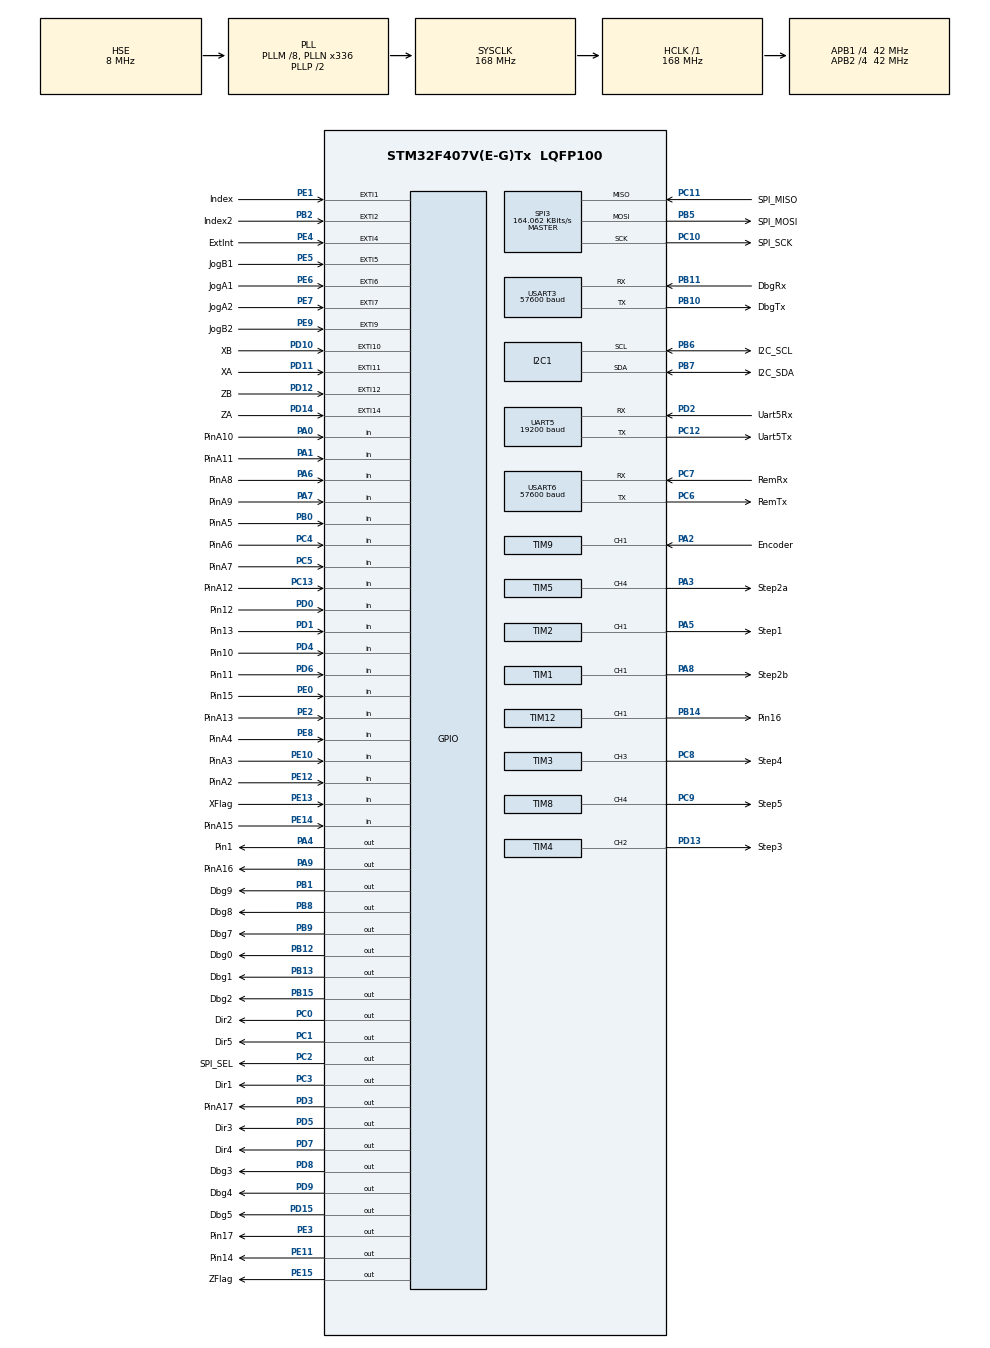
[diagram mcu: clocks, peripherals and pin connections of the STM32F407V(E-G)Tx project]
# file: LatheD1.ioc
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IWDG.Prescaler=IWDG_PRESCALER_32
Mcu.Family=STM32F4
Mcu.Name=STM32F407V(E-G)Tx
Mcu.Package=LQFP100
NVIC.EXTI15_10_IRQn=true\:5\:0\:true\:false\:false\:true\:false\:true
NVIC.EXTI2_IRQn=true\:5\:0\:true\:false\:false\:true\:false\:true
NVIC.EXTI4_IRQn=true\:5\:0\:true\:false\:false\:true\:false\:true
NVIC.EXTI9_5_IRQn=true\:5\:0\:true\:false\:false\:true\:false\:true
NVIC.PriorityGroup=NVIC_PRIORITYGROUP_4
NVIC.SPI3_IRQn=true\:6\:0\:true\:false\:false\:true\:false\:true
NVIC.TIM1_BRK_TIM9_IRQn=true\:6\:0\:true\:false\:false\:true\:false\:true
NVIC.TIM1_TRG_COM_TIM11_IRQn=true\:6\:0\:true\:false\:false\:true\:false\:true
NVIC.TIM1_UP_TIM10_IRQn=true\:4\:0\:true\:false\:false\:true\:false\:true
NVIC.TIM2_IRQn=true\:3\:0\:true\:false\:false\:true\:false\:true
NVIC.TIM3_IRQn=true\:2\:0\:true\:false\:false\:true\:false\:true
NVIC.TIM4_IRQn=true\:4\:0\:true\:false\:false\:true\:false\:true
NVIC.TIM5_IRQn=true\:2\:0\:true\:false\:false\:true\:false\:true
NVIC.TIM7_IRQn=true\:5\:0\:true\:false\:false\:true\:false\:true
NVIC.TIM8_BRK_TIM12_IRQn=true\:5\:0\:true\:false\:false\:true\:false\:true
NVIC.TIM8_TRG_COM_TIM14_IRQn=true\:0\:0\:false\:false\:false\:true\:false\:true
NVIC.TIM8_UP_TIM13_IRQn=true\:5\:0\:true\:false\:false\:true\:false\:true
NVIC.UART5_IRQn=true\:6\:0\:true\:false\:false\:true\:false\:true
NVIC.USART6_IRQn=true\:6\:0\:true\:false\:false\:true\:false\:true
PA0-WKUP.GPIO_Label=PinA10
PA0-WKUP.Signal=GPIO_Input
PA1.GPIO_Label=PinA11
PA1.Signal=GPIO_Input
PA13.Mode=JTAG_5_pins
PA13.Signal=SYS_JTMS-SWDIO
PA14.Mode=JTAG_5_pins
PA14.Signal=SYS_JTCK-SWCLK
PA15.Mode=JTAG_5_pins
PA15.Signal=SYS_JTDI
PA2.GPIO_Label=Encoder
PA2.Signal=S_TIM9_CH1
PA3.GPIO_Label=Step2a
PA3.Signal=S_TIM5_CH4
PA4.GPIO_Label=Pin1
PA4.Signal=GPIO_Output
PA5.GPIO_Label=Step1
PA5.Signal=S_TIM2_CH1_ETR
PA6.GPIO_Label=PinA8
PA6.Signal=GPIO_Input
PA7.GPIO_Label=PinA9
PA7.Signal=GPIO_Input
PA8.GPIO_Label=Step2b
PA8.Signal=S_TIM1_CH1
PA9.GPIO_Label=PinA16
PA9.Signal=GPIO_Output
PB0.GPIO_Label=PinA5
PB0.Signal=GPIO_Input
PB1.GPIO_Label=Dbg9
PB1.Signal=GPIO_Output
PB10.GPIO_Label=DbgTx
PB10.Mode=Asynchronous
PB10.Signal=USART3_TX
PB11.GPIO_Label=DbgRx
PB11.Mode=Asynchronous
PB11.Signal=USART3_RX
PB12.GPIO_Label=Dbg0
PB12.Signal=GPIO_Output
PB13.GPIO_Label=Dbg1
PB13.Signal=GPIO_Output
PB14.GPIO_Label=Pin16
PB14.Signal=S_TIM12_CH1
PB15.GPIO_Label=Dbg2
PB15.Signal=GPIO_Output
PB2.GPIO_Label=Index2
PB2.Signal=GPXTI2
PB3.Mode=JTAG_5_pins
PB3.Signal=SYS_JTDO-SWO
PB4.Mode=JTAG_5_pins
PB4.Signal=SYS_JTRST
PB5.GPIO_Label=SPI_MOSI
PB5.Mode=Full_Duplex_Master
PB5.Signal=SPI3_MOSI
PB6.GPIO_Label=I2C_SCL
PB6.GPIO_Pu=GPIO_PULLUP
PB6.Mode=I2C
PB6.Signal=I2C1_SCL
PB7.GPIO_Label=I2C_SDA
PB7.GPIO_Pu=GPIO_PULLUP
PB7.Mode=I2C
PB7.Signal=I2C1_SDA
PB8.GPIO_Label=Dbg8
PB8.Signal=GPIO_Output
PB9.GPIO_Label=Dbg7
PB9.Signal=GPIO_Output
PC0.GPIO_Label=Dir2
PC0.Signal=GPIO_Output
PC1.GPIO_Label=Dir5
PC1.Signal=GPIO_Output
PC10.GPIO_Label=SPI_SCK
PC10.Mode=Full_Duplex_Master
PC10.Signal=SPI3_SCK
PC11.GPIO_Label=SPI_MISO
PC11.Mode=Full_Duplex_Master
PC11.Signal=SPI3_MISO
PC12.GPIO_Label=Uart5Tx
PC12.Mode=Asynchronous
PC12.Signal=UART5_TX
PC13-ANTI_TAMP.GPIO_Label=PinA12
PC13-ANTI_TAMP.Signal=GPIO_Input
PC2.GPIO_Label=SPI_SEL
PC2.Signal=GPIO_Output
PC3.GPIO_Label=Dir1
PC3.Signal=GPIO_Output
PC4.GPIO_Label=PinA6
PC4.Signal=GPIO_Input
PC5.GPIO_Label=PinA7
PC5.Signal=GPIO_Input
PC6.GPIO_Label=RemTx
PC6.Mode=Asynchronous
PC6.Signal=USART6_TX
PC7.GPIO_Label=RemRx
PC7.Mode=Asynchronous
PC7.Signal=USART6_RX
PC8.GPIO_Label=Step4
PC8.Signal=S_TIM3_CH3
PC9.GPIO_Label=Step5
PC9.GPIO_Speed=GPIO_SPEED_FREQ_LOW
PC9.Signal=S_TIM8_CH4
PD0.GPIO_Label=Pin12
PD0.Signal=GPIO_Input
PD1.GPIO_Label=Pin13
PD1.Signal=GPIO_Input
PD10.GPIO_Label=XB
PD10.GPIO_ModeDefaultEXTI=GPIO_MODE_IT_RISING_FALLING
PD10.Signal=GPXTI10
PD11.GPIO_Label=XA
PD11.GPIO_ModeDefaultEXTI=GPIO_MODE_IT_RISING_FALLING
PD11.Signal=GPXTI11
PD12.GPIO_Label=ZB
PD12.GPIO_ModeDefaultEXTI=GPIO_MODE_IT_RISING_FALLING
PD12.Signal=GPXTI12
PD13.GPIO_Label=Step3
PD13.Signal=S_TIM4_CH2
PD14.GPIO_Label=ZA
PD14.GPIO_ModeDefaultEXTI=GPIO_MODE_IT_RISING_FALLING
PD14.Signal=GPXTI14
PD15.GPIO_Label=Dbg5
PD15.Signal=GPIO_Output
PD2.GPIO_Label=Uart5Rx
PD2.Mode=Asynchronous
PD2.Signal=UART5_RX
PD3.GPIO_Label=PinA17
PD3.Signal=GPIO_Output
PD4.GPIO_Label=Pin10
PD4.Signal=GPIO_Input
PD5.GPIO_Label=Dir3
PD5.Signal=GPIO_Output
PD6.GPIO_Label=Pin11
PD6.Signal=GPIO_Input
PD7.GPIO_Label=Dir4
PD7.Signal=GPIO_Output
PD8.GPIO_Label=Dbg3
PD8.Signal=GPIO_Output
PD9.GPIO_Label=Dbg4
PD9.Signal=GPIO_Output
PE0.GPIO_Label=Pin15
PE0.Signal=GPIO_Input
PE1.GPIO_Label=Index
PE1.Signal=GPXTI1
PE10.GPIO_Label=PinA3
PE10.Signal=GPIO_Input
PE11.GPIO_Label=Pin14
PE11.Signal=GPIO_Output
PE12.GPIO_Label=PinA2
PE12.Signal=GPIO_Input
PE13.GPIO_Label=XFlag
PE13.Signal=GPIO_Input
PE14.GPIO_Label=PinA15
PE14.Signal=GPIO_Input
PE15.GPIO_Label=ZFlag
PE15.Signal=GPIO_Output
PE2.GPIO_Label=PinA13
PE2.Signal=GPIO_Input
PE3.GPIO_Label=Pin17
PE3.Signal=GPIO_Output
PE4.GPIO_Label=ExtInt
PE4.Signal=GPXTI4
PE5.GPIO_Label=JogB1
PE5.GPIO_ModeDefaultEXTI=GPIO_MODE_IT_RISING_FALLING
PE5.Signal=GPXTI5
PE6.GPIO_Label=JogA1
PE6.GPIO_ModeDefaultEXTI=GPIO_MODE_IT_RISING_FALLING
PE6.Signal=GPXTI6
PE7.GPIO_Label=JogA2
PE7.GPIO_ModeDefaultEXTI=GPIO_MODE_IT_RISING_FALLING
PE7.Signal=GPXTI7
PE8.GPIO_Label=PinA4
PE8.Signal=GPIO_Input
PE9.GPIO_Label=JogB2
PE9.GPIO_ModeDefaultEXTI=GPIO_MODE_IT_RISING_FALLING
PE9.Signal=GPXTI9
PH0-OSC_IN.Mode=HSE-External-Oscillator
PH0-OSC_IN.Signal=RCC_OSC_IN
PH1-OSC_OUT.Mode=HSE-External-Oscillator
PH1-OSC_OUT.Signal=RCC_OSC_OUT
ProjectManager.HeapSize=0x400
ProjectManager.StackSize=0x200
ProjectManager.TargetToolchain=STM32CubeIDE
RCC.48MHZClocksFreq_Value=48000000
RCC.AHBFreq_Value=168000000
RCC.APB1CLKDivider=RCC_HCLK_DIV4
RCC.APB1Freq_Value=42000000
RCC.APB1TimFreq_Value=84000000
RCC.APB2CLKDivider=RCC_HCLK_DIV4
RCC.APB2Freq_Value=42000000
RCC.APB2TimFreq_Value=84000000
RCC.CortexFreq_Value=168000000
RCC.HCLKFreq_Value=168000000
RCC.HSE_VALUE=8000000
RCC.HSI_VALUE=16000000
RCC.LSE_VALUE=32768
RCC.PLLM=8
RCC.PLLN=336
RCC.PLLQ=7
RCC.PLLSourceVirtual=RCC_PLLSOURCE_HSE
RCC.SYSCLKFreq_VALUE=168000000
RCC.SYSCLKSource=RCC_SYSCLKSOURCE_PLLCLK
RCC.VCOOutputFreq_Value=336000000
SH.S_TIM12_CH1.0=TIM12_CH1,PWM Generation1 CH1
SH.S_TIM1_CH1.0=TIM1_CH1,PWM Generation1 CH1
SH.S_TIM2_CH1_ETR.0=TIM2_CH1,PWM Generation1 CH1
SH.S_TIM3_CH3.0=TIM3_CH3,PWM Generation3 CH3
SH.S_TIM4_CH2.0=TIM4_CH2,PWM Generation2 CH2
SH.S_TIM5_CH4.0=TIM5_CH4,PWM Generation4 CH4
SH.S_TIM8_CH4.0=TIM8_CH4,PWM Generation4 CH4
SH.S_TIM9_CH1.0=TIM9_CH1,Input_Capture1_from_TI1
SPI3.BaudRatePrescaler=SPI_BAUDRATEPRESCALER_256
SPI3.CalculateBaudRate=164.062 KBits/s
SPI3.Direction=SPI_DIRECTION_2LINES
SPI3.Mode=SPI_MODE_MASTER
SPI3.VirtualType=VM_MASTER
TIM1.Channel-PWM\ Generation1\ CH1=TIM_CHANNEL_1
TIM1.CounterMode=TIM_COUNTERMODE_DOWN
TIM1.Period=65535
TIM1.Prescaler=0
TIM1.Pulse-PWM\ Generation1\ CH1=100
TIM10.Period=65535
TIM10.Prescaler=2560
TIM11.Period=10000
TIM12.Channel-PWM\ Generation1\ CH1=TIM_CHANNEL_1
TIM2.Channel-PWM\ Generation1\ CH1=TIM_CHANNEL_1
TIM2.CounterMode=TIM_COUNTERMODE_DOWN
TIM2.OCPolarity_1=TIM_OCPOLARITY_LOW
TIM2.Period=100000
TIM2.Prescaler=0
TIM3.Channel-PWM\ Generation3\ CH3=TIM_CHANNEL_3
TIM3.CounterMode=TIM_COUNTERMODE_DOWN
TIM3.Period=10000
TIM3.TIM_MasterOutputTrigger=TIM_TRGO_UPDATE
TIM3.TIM_MasterSlaveMode=TIM_MASTERSLAVEMODE_ENABLE
TIM4.Channel-PWM\ Generation2\ CH2=TIM_CHANNEL_2
TIM4.CounterMode=TIM_COUNTERMODE_DOWN
TIM4.Period=9999
TIM4.TIM_MasterOutputTrigger=TIM_TRGO_UPDATE
TIM4.TIM_MasterSlaveMode=TIM_MASTERSLAVEMODE_DISABLE
TIM5.Channel-PWM\ Generation4\ CH4=TIM_CHANNEL_4
TIM5.CounterMode=TIM_COUNTERMODE_DOWN
TIM5.OCPolarity_4=TIM_OCPOLARITY_LOW
TIM5.Period=100000
TIM5.Prescaler=0
TIM7.Period=10000
TIM8.Channel-PWM\ Generation4\ CH4=TIM_CHANNEL_4
TIM8.CounterMode=TIM_COUNTERMODE_DOWN
TIM8.Period=1000
TIM8.Prescaler=0
TIM8.Pulse-PWM\ Generation4\ CH4=100
TIM8.TIM_MasterOutputTrigger=TIM_TRGO_UPDATE
TIM8.TIM_MasterSlaveMode=TIM_MASTERSLAVEMODE_ENABLE
TIM9.Channel-Input_Capture1_from_TI1=TIM_CHANNEL_1
UART5.BaudRate=19200
UART5.VirtualMode=Asynchronous
USART3.BaudRate=57600
USART3.VirtualMode=VM_ASYNC
USART6.BaudRate=57600
USART6.VirtualMode=VM_ASYNC
VP_IWDG_VS_IWDG.Mode=IWDG_Activate
VP_TIM10_VS_ClockSourceINT.Mode=Enable_Timer
VP_TIM11_VS_ClockSourceINT.Mode=Enable_Timer
VP_TIM12_VS_ClockSourceINT.Mode=Internal
VP_TIM13_VS_ClockSourceINT.Mode=Enable_Timer
VP_TIM14_VS_ClockSourceINT.Mode=Enable_Timer
VP_TIM1_VS_ClockSourceINT.Mode=Internal
VP_TIM2_VS_ClockSourceINT.Mode=Internal
VP_TIM3_VS_ClockSourceINT.Mode=Internal
VP_TIM4_VS_ClockSourceINT.Mode=Internal
VP_TIM4_VS_ClockSourceITR.Mode=TriggerSource_ITR2
VP_TIM4_VS_ControllerModeTrigger.Mode=Trigger Mode
VP_TIM5_VS_ClockSourceINT.Mode=Internal
VP_TIM6_VS_ClockSourceINT.Mode=Enable_Timer
VP_TIM7_VS_ClockSourceINT.Mode=Enable_Timer
VP_TIM8_VS_ClockSourceINT.Mode=Internal
board=LatheD

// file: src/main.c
/* USER CODE BEGIN Header */
/**
  ******************************************************************************
  * @file           : main.c
  * @brief          : Main program body
  ******************************************************************************
  ** This notice applies to any and all portions of this file
  * that are not between comment pairs USER CODE BEGIN and
  * USER CODE END. Other portions of this file, whether
  * inserted by the user or by software development tools
  * are owned by their respective copyright owners.
  *
  * COPYRIGHT(c) 2018 STMicroelectronics
  *
  * Redistribution and use in source and binary forms, with or without modification,
  * are permitted provided that the following conditions are met:
  *   1. Redistributions of source code must retain the above copyright notice,
  *      this list of conditions and the following disclaimer.
  *   2. Redistributions in binary form must reproduce the above copyright notice,
  *      this list of conditions and the following disclaimer in the documentation
  *      and/or other materials provided with the distribution.
  *   3. Neither the name of STMicroelectronics nor the names of its contributors
  *      may be used to endorse or promote products derived from this software
  *      without specific prior written permission.
  *
  * THIS SOFTWARE IS PROVIDED BY THE COPYRIGHT HOLDERS AND CONTRIBUTORS "AS IS"
  * AND ANY EXPRESS OR IMPLIED WARRANTIES, INCLUDING, BUT NOT LIMITED TO, THE
  * IMPLIED WARRANTIES OF MERCHANTABILITY AND FITNESS FOR A PARTICULAR PURPOSE ARE
  * DISCLAIMED. IN NO EVENT SHALL THE COPYRIGHT HOLDER OR CONTRIBUTORS BE LIABLE
  * FOR ANY DIRECT, INDIRECT, INCIDENTAL, SPECIAL, EXEMPLARY, OR CONSEQUENTIAL
  * DAMAGES (INCLUDING, BUT NOT LIMITED TO, PROCUREMENT OF SUBSTITUTE GOODS OR
  * SERVICES; LOSS OF USE, DATA, OR PROFITS; OR BUSINESS INTERRUPTION) HOWEVER
  * CAUSED AND ON ANY THEORY OF LIABILITY, WHETHER IN CONTRACT, STRICT LIABILITY,
  * OR TORT (INCLUDING NEGLIGENCE OR OTHERWISE) ARISING IN ANY WAY OUT OF THE USE
  * OF THIS SOFTWARE, EVEN IF ADVISED OF THE POSSIBILITY OF SUCH DAMAGE.
  *
  ******************************************************************************
  */
#include "stm32f4xx_hal.h"
/* USER CODE END Header */
#include "main.h"
#include "i2c.h"
#include "iwdg.h"
#include "spi.h"
#include "tim.h"
#include "usart.h"
#include "gpio.h"

/* USER CODE BEGIN PV */
/* Private variables ---------------------------------------------------------*/

/* USER CODE END PV */

void SystemClock_Config(void);
/* USER CODE BEGIN PFP */
void mainLoop();

/* USER CODE END PFP */

int main(void)
{

  /* MCU Configuration--------------------------------------------------------*/

  /* Reset of all peripherals, Initializes the Flash interface and the Systick. */
  HAL_Init();

  /* Configure the system clock */
  SystemClock_Config();

  /* Initialize all configured peripherals */
  MX_GPIO_Init();
  MX_TIM1_Init();
  MX_TIM2_Init();
  MX_TIM3_Init();
  MX_TIM4_Init();
  MX_TIM5_Init();
  MX_TIM8_Init();
  MX_TIM12_Init();
  MX_UART5_Init();
  MX_TIM7_Init();
  MX_TIM14_Init();
  MX_TIM11_Init();
  MX_TIM10_Init();
  MX_SPI3_Init();
  MX_TIM6_Init();
  MX_TIM13_Init();
  MX_I2C1_Init();
  MX_USART3_UART_Init();
  MX_USART6_UART_Init();
  MX_TIM9_Init();
  MX_IWDG_Init();
  /* USER CODE BEGIN 2 */

  mainLoop();

  /* USER CODE END 2 */

  /* Infinite loop */
  while (1)
  {

  }
}

void SystemClock_Config(void)
{
  RCC_OscInitTypeDef RCC_OscInitStruct = {0};
  RCC_ClkInitTypeDef RCC_ClkInitStruct = {0};

  /** Configure the main internal regulator output voltage
  */
  __HAL_RCC_PWR_CLK_ENABLE();
  __HAL_PWR_VOLTAGESCALING_CONFIG(PWR_REGULATOR_VOLTAGE_SCALE1);

  /** Initializes the RCC Oscillators according to the specified parameters
  * in the RCC_OscInitTypeDef structure.
  */
  RCC_OscInitStruct.OscillatorType = RCC_OSCILLATORTYPE_LSI|RCC_OSCILLATORTYPE_HSE;
  RCC_OscInitStruct.HSEState = RCC_HSE_ON;
  RCC_OscInitStruct.LSIState = RCC_LSI_ON;
  RCC_OscInitStruct.PLL.PLLState = RCC_PLL_ON;
  RCC_OscInitStruct.PLL.PLLSource = RCC_PLLSOURCE_HSE;
  RCC_OscInitStruct.PLL.PLLM = 8;
  RCC_OscInitStruct.PLL.PLLN = 336;
  RCC_OscInitStruct.PLL.PLLP = RCC_PLLP_DIV2;
  RCC_OscInitStruct.PLL.PLLQ = 7;
  if (HAL_RCC_OscConfig(&RCC_OscInitStruct) != HAL_OK)
  {
    Error_Handler();
  }

  /** Initializes the CPU, AHB and APB buses clocks
  */
  RCC_ClkInitStruct.ClockType = RCC_CLOCKTYPE_HCLK|RCC_CLOCKTYPE_SYSCLK
                              |RCC_CLOCKTYPE_PCLK1|RCC_CLOCKTYPE_PCLK2;
  RCC_ClkInitStruct.SYSCLKSource = RCC_SYSCLKSOURCE_PLLCLK;
  RCC_ClkInitStruct.AHBCLKDivider = RCC_SYSCLK_DIV1;
  RCC_ClkInitStruct.APB1CLKDivider = RCC_HCLK_DIV4;
  RCC_ClkInitStruct.APB2CLKDivider = RCC_HCLK_DIV4;

  if (HAL_RCC_ClockConfig(&RCC_ClkInitStruct, FLASH_LATENCY_5) != HAL_OK)
  {
    Error_Handler();
  }
}

void Error_Handler(void)
{
  while(1)
  {
  }
}
